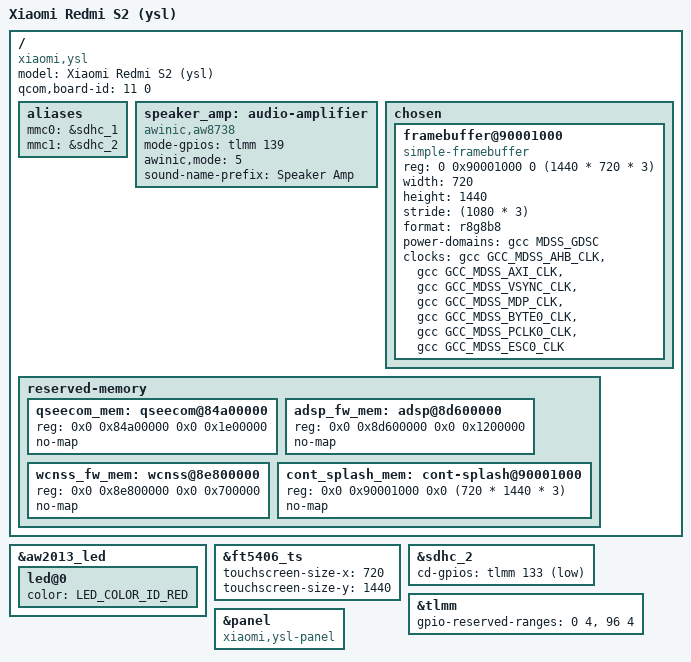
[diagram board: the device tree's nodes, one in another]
// SPDX-License-Identifier: BSD-3-Clause
/dts-v1/;

#include "msm8953-xiaomi-common.dtsi"

/delete-node/ &cont_splash_mem;
/delete-node/ &qseecom_mem;

/ {
//todo board-id and pmic probably here too
	model = "Xiaomi Redmi S2 (ysl)";
	compatible = "xiaomi,ysl", "qcom,msm8953";
	qcom,board-id = <11 0>;

	aliases {
		mmc0 = &sdhc_1;
		mmc1 = &sdhc_2;
	};
//verify
	speaker_amp: audio-amplifier {
		compatible = "awinic,aw8738";
		mode-gpios = <&tlmm 139 GPIO_ACTIVE_HIGH>;
		awinic,mode = <5>;
		sound-name-prefix = "Speaker Amp";
	};

	chosen {
		#address-cells = <2>;
		#size-cells = <2>;
		ranges;

		framebuffer@90001000 {
			compatible = "simple-framebuffer";
			reg = <0 0x90001000 0 (1440 * 720 * 3)>;

			width = <720>;
			height = <1440>;
			stride = <(1080 * 3)>;
			format = "r8g8b8";

			power-domains = <&gcc MDSS_GDSC>;

			clocks = <&gcc GCC_MDSS_AHB_CLK>,
				 <&gcc GCC_MDSS_AXI_CLK>,
				 <&gcc GCC_MDSS_VSYNC_CLK>,
				 <&gcc GCC_MDSS_MDP_CLK>,
				 <&gcc GCC_MDSS_BYTE0_CLK>,
				 <&gcc GCC_MDSS_PCLK0_CLK>,
				 <&gcc GCC_MDSS_ESC0_CLK>;
		};
	};

	reserved-memory {
		qseecom_mem: qseecom@84a00000 {
			reg = <0x0 0x84a00000 0x0 0x1e00000>;
			no-map;
		};
		
		adsp_fw_mem: adsp@8d600000 {
			reg = <0x0 0x8d600000 0x0 0x1200000>;
			no-map;
		};

		wcnss_fw_mem: wcnss@8e800000 {
			reg = <0x0 0x8e800000 0x0 0x700000>;
			no-map;
		};

		cont_splash_mem: cont-splash@90001000 {
			reg = <0x0 0x90001000 0x0 (720 * 1440 * 3)>;
			no-map;
		};
	};
};

&aw2013_led {
	status = "okay";

	led@0 {
		color = <LED_COLOR_ID_RED>;
		};
};

&ft5406_ts {
	status = "okay";

	touchscreen-size-x = <720>;
	touchscreen-size-y = <1440>;

};

&sdhc_2 {
	cd-gpios = <&tlmm 133 GPIO_ACTIVE_LOW>;
};

&tlmm {
	gpio-reserved-ranges = <0 4>, <96 4>;
};

&panel {
	compatible = "xiaomi,ysl-panel";
};
